# HC32F334FAUI register map
File version: 1.0
CPU: CM4 r0p1, little endian, MPU, FPU, 4 interrupt priority bits
Registers are 32-bit, read-write, reset 0x0 unless marked. A register's access mark holds for its fields unless they carry their own. Offsets are from the block's base; [hi:lo] are bit positions; {n}, {i} and the like mark numbered series.

## RMU
Base 0x4004CCE0
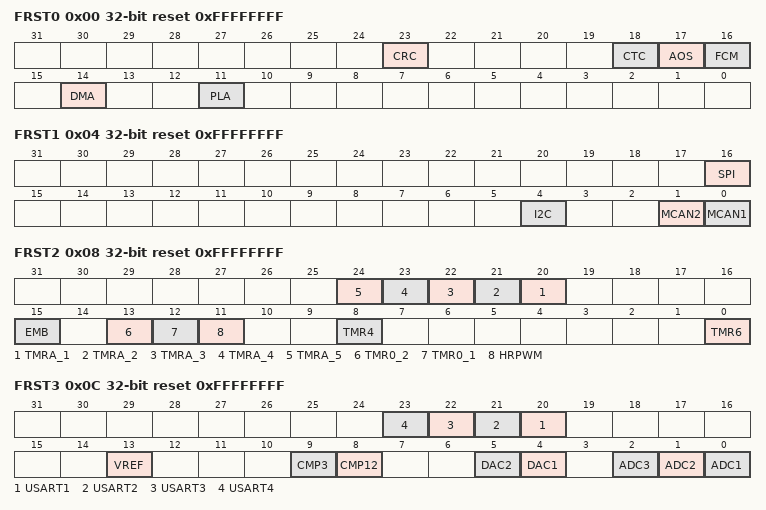
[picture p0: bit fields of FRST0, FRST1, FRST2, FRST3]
0x00 FRST0 reset 0xFFFFFFFF
  [23] CRC, [18] CTC, [17] AOS, [16] FCM, [14] DMA, [11] PLA
0x04 FRST1 reset 0xFFFFFFFF
  [16] SPI, [4] I2C, [1] MCAN2, [0] MCAN1
0x08 FRST2 reset 0xFFFFFFFF
  [n+19] TMRA_{n} (n=1..5), [15] EMB, [13] TMR0_2, [12] TMR0_1, [11] HRPWM, [8] TMR4, [0] TMR6
0x0C FRST3 reset 0xFFFFFFFF
  [n+19] USART{n} (n=1..4), [13] VREF, [9] CMP3, [8] CMP12, [5] DAC2, [4] DAC1, [2] ADC3, [1] ADC2, [0] ADC1
0x10 PRSTCR0 8-bit reset 0x40
  [5] LKUPREN
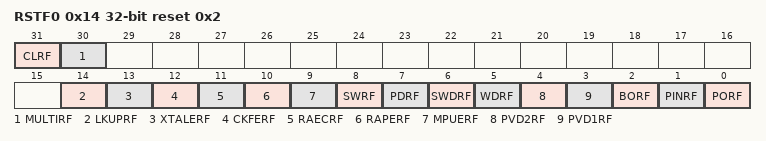
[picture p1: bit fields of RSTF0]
0x14 RSTF0 reset 0x2
  [31] CLRF, [30] MULTIRF, [14] LKUPRF, [13] XTALERF, [12] CKFERF, [11] RAECRF, [10] RAPERF, [9] MPUERF, [8] SWRF, [7] PDRF, [6] SWDRF, [5] WDRF, [4] PVD2RF, [3] PVD1RF, [2] BORF, [1] PINRF, [0] PORF

## RTC
Base 0x4004C000
0x00 CR0 8-bit
  [0] RESET
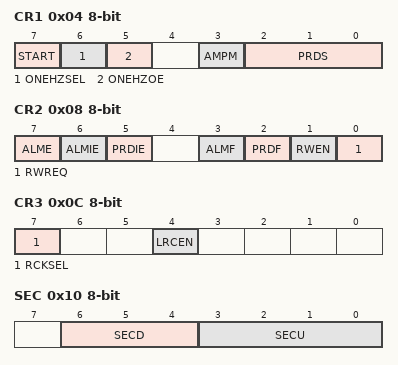
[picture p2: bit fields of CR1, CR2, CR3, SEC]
0x04 CR1 8-bit
  [7] START, [6] ONEHZSEL, [5] ONEHZOE, [3] AMPM, [2:0] PRDS
0x08 CR2 8-bit
  [7] ALME, [6] ALMIE, [5] PRDIE, [3] ALMF, [2] PRDF, [1] RWEN, [0] RWREQ
0x0C CR3 8-bit
  [7] RCKSEL, [4] LRCEN
0x10 SEC 8-bit
  [6:4] SECD, [3:0] SECU
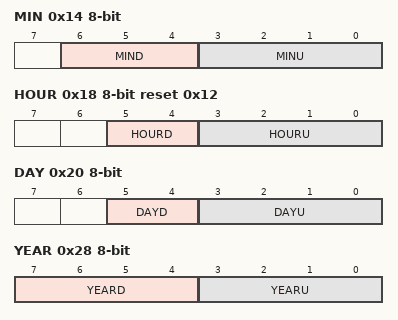
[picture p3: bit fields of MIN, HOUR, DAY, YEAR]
0x14 MIN 8-bit
  [6:4] MIND, [3:0] MINU
0x18 HOUR 8-bit reset 0x12
  [5:4] HOURD, [3:0] HOURU
0x1C WEEK 8-bit
  [2:0] WEEK
0x20 DAY 8-bit
  [5:4] DAYD, [3:0] DAYU
0x24 MON 8-bit
  [4:0] MON
0x28 YEAR 8-bit
  [7:4] YEARD, [3:0] YEARU
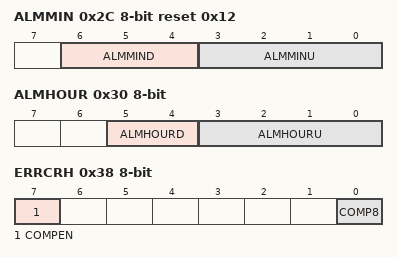
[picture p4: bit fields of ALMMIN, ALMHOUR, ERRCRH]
0x2C ALMMIN 8-bit reset 0x12
  [6:4] ALMMIND, [3:0] ALMMINU
0x30 ALMHOUR 8-bit
  [5:4] ALMHOURD, [3:0] ALMHOURU
0x34 ALMWEEK 8-bit
  [6:0] ALMWEEK
0x38 ERRCRH 8-bit
  [7] COMPEN, [0] COMP8
0x3C ERRCRL 8-bit reset 0x20

## SPI
Base 0x4001C000
0x00 DR
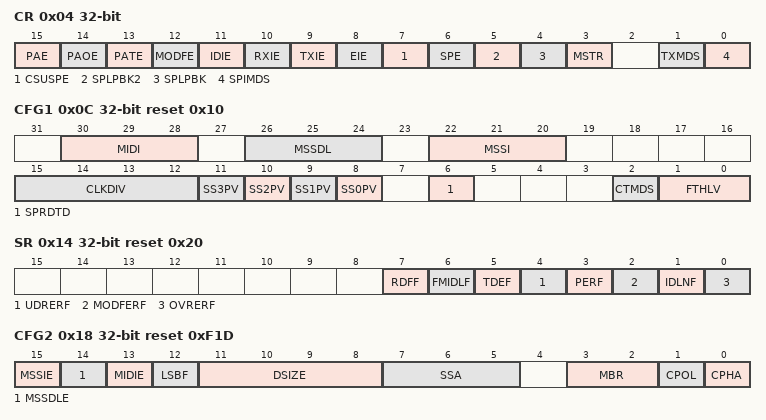
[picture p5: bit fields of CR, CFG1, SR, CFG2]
0x04 CR
  [15] PAE, [14] PAOE, [13] PATE, [12] MODFE, [11] IDIE, [10] RXIE, [9] TXIE, [8] EIE, [7] CSUSPE, [6] SPE, [5] SPLPBK2, [4] SPLPBK, [3] MSTR, [1] TXMDS, [0] SPIMDS
0x0C CFG1 reset 0x10
  [30:28] MIDI, [26:24] MSSDL, [22:20] MSSI, [15:12] CLKDIV, [n+8] SS{n}PV (n=0..3), [6] SPRDTD, [2] CTMDS, [1:0] FTHLV
0x14 SR reset 0x20
  [7] RDFF ro, [6] FMIDLF ro, [5] TDEF ro, [4] UDRERF, [3] PERF, [2] MODFERF, [1] IDLNF ro, [0] OVRERF
0x18 CFG2 reset 0xF1D
  [15] MSSIE, [14] MSSDLE, [13] MIDIE, [12] LSBF, [11:8] DSIZE, [7:5] SSA, [3:2] MBR, [1] CPOL, [0] CPHA

## SRAMC
Base 0x40050800
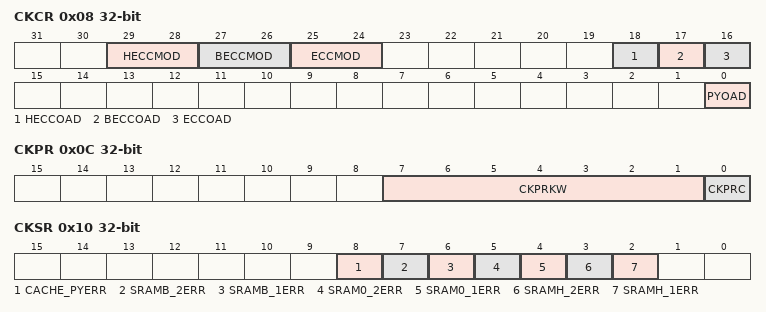
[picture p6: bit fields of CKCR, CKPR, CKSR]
0x08 CKCR
  [29:28] HECCMOD, [27:26] BECCMOD, [25:24] ECCMOD, [18] HECCOAD, [17] BECCOAD, [16] ECCOAD, [0] PYOAD
0x0C CKPR
  [7:1] CKPRKW, [0] CKPRC
0x10 CKSR
  [8] CACHE_PYERR, [7] SRAMB_2ERR, [6] SRAMB_1ERR, [5] SRAM0_2ERR, [4] SRAM0_1ERR, [3] SRAMH_2ERR, [2] SRAMH_1ERR
0x14 SRAM0_EIEN
  [0] EIEN
0x18 SRAM0_EIBIT0
0x1C SRAM0_EIBIT1
  [6:0] EIBIT
0x20 SRAM0_ECCERRADDR ro
  [14:0] ECCERRADDR
0x54 SRAMH_EIEN
  [0] EIEN
0x58 SRAMH_EIBIT0
0x5C SRAMH_EIBIT1
  [6:0] EIBIT
0x60 SRAMH_ECCERRADDR ro
  [14:0] ECCERRADDR
0x64 SRAMB_EIEN
  [0] EIEN
0x68 SRAMB_EIBIT0
0x6C SRAMB_EIBIT1
  [6:0] EIBIT
0x70 SRAMB_ECCERRADDR ro
  [11:0] ECCERRADDR

## SWDT
Base 0x40049400
Same registers: WDT 0x40049000
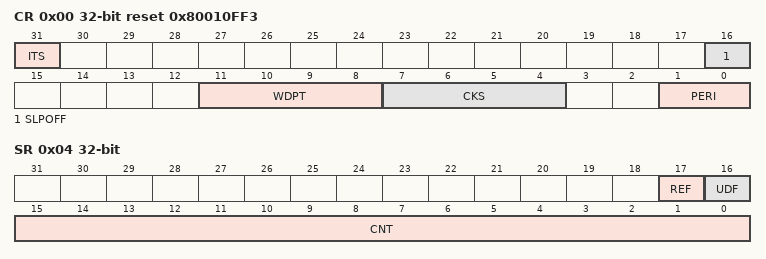
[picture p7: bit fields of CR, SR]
0x00 CR reset 0x80010FF3
  [31] ITS, [16] SLPOFF, [11:8] WDPT, [7:4] CKS, [1:0] PERI
0x04 SR
  [17] REF, [16] UDF, [15:0] CNT ro
0x08 RR
  [15:0] RF

## TMR01 — desc TMR0
Base 0x40024000
Same registers: TMR02 0x40024400
0x00 CNTAR
  [15:0] CNTA
0x04 CNTBR
  [15:0] CNTB
0x08 CMPAR reset 0xFFFF
  [15:0] CMPA
0x0C CMPBR reset 0xFFFF
  [15:0] CMPB
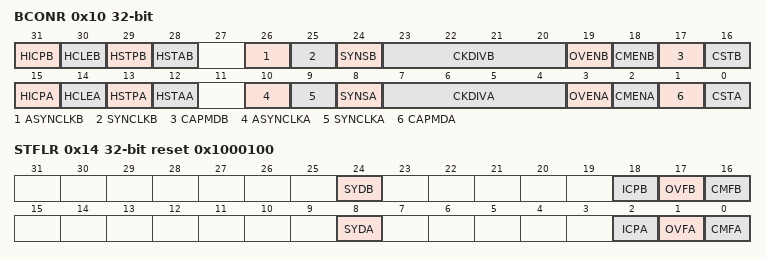
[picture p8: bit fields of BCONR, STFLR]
0x10 BCONR
  [31] HICPB, [30] HCLEB, [29] HSTPB, [28] HSTAB, [26] ASYNCLKB, [25] SYNCLKB, [24] SYNSB, [23:20] CKDIVB, [19] OVENB, [18] CMENB, [17] CAPMDB, [16] CSTB, [15] HICPA, [14] HCLEA, [13] HSTPA, [12] HSTAA, [10] ASYNCLKA, [9] SYNCLKA, [8] SYNSA, [7:4] CKDIVA, [3] OVENA, [2] CMENA, [1] CAPMDA, [0] CSTA
0x14 STFLR reset 0x1000100
  [24] SYDB ro, [18] ICPB, [17] OVFB, [16] CMFB, [8] SYDA ro, [2] ICPA, [1] OVFA, [0] CMFA
